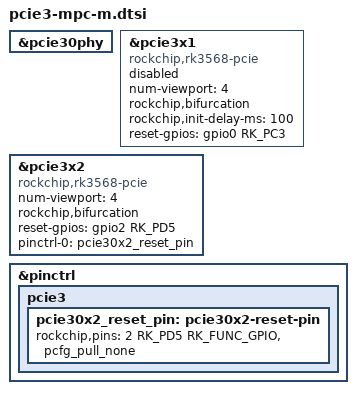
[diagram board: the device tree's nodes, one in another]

&pcie30phy {
	status = "okay";
};

/*
	This controller has one lane 0.
	The lane 0 is connected to nowhere
	If bifurcation mode is cativated the lane 0 is controlled by pcie3x1.
*/
&pcie3x1 {
	compatible = "rockchip,rk3568-pcie";
	num-viewport = <4>;
	rockchip,bifurcation;
	rockchip,init-delay-ms = <100>;
//	TODO
	reset-gpios = <&gpio0 RK_PC3 GPIO_ACTIVE_HIGH>;

	status = "disabled";
};

/*
	This controller has two lanes which can be organized in PCIE3 x2 mode or in case of enabled bifurcation in PCIE3 x1 mode.
	The lane 0 is connected to X16.
	If bifurcation mode is cativated the lane 1 is controlled by pcie3x1, lane 0 is controlled by pcie3x2
*/
&pcie3x2 {
	compatible = "rockchip,rk3568-pcie";
	num-viewport = <4>;
	rockchip,bifurcation;
	// PCIE30_PERSTn
	reset-gpios = <&gpio2 RK_PD5 GPIO_ACTIVE_HIGH>;
	pinctrl-names = "default";
	pinctrl-0 = <&pcie30x2_reset_pin>;
	status = "okay";
};

&pinctrl {
	pcie3 {

		pcie30x2_reset_pin: pcie30x2-reset-pin {
/*
			PCIE30_PERSTn
			0 -> 0
			1 -> 1
*/
			rockchip,pins = <2 RK_PD5 RK_FUNC_GPIO &pcfg_pull_none>;
		};
	};
};

